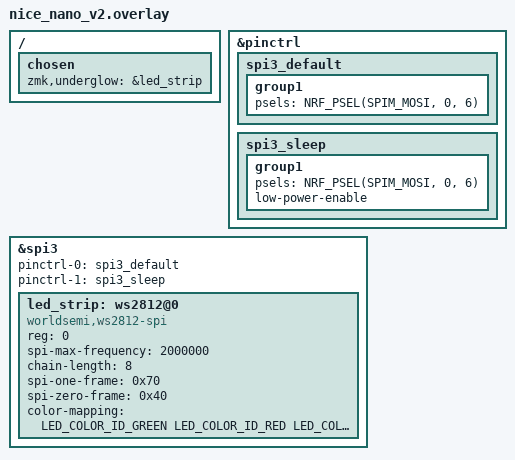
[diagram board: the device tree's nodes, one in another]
#include <dt-bindings/led/led.h>

/ {
    chosen {
        zmk,underglow = &led_strip;
    };
};

&pinctrl {
    spi3_default: spi3_default {
        group1 { psels = <NRF_PSEL(SPIM_MOSI, 0, 6)>; };
    };

    spi3_sleep: spi3_sleep {
        group1 {
            psels = <NRF_PSEL(SPIM_MOSI, 0, 6)>;
            low-power-enable;
        };
    };
};

&spi3 {
    status = "okay";
    pinctrl-0 = <&spi3_default>;
    pinctrl-1 = <&spi3_sleep>;
    pinctrl-names = "default", "sleep";

    /* Supprime le ws2812@0 défini par le shield, puis le recrée avec TON chain-length */
    /delete-node/ ws2812@0;

    led_strip: ws2812@0 {
        compatible = "worldsemi,ws2812-spi";
        reg = <0>;
        spi-max-frequency = <2000000>;

        chain-length = <8>;   /* mets 8 pour tester */
        spi-one-frame = <0x70>;
        spi-zero-frame = <0x40>;
        color-mapping = <LED_COLOR_ID_GREEN LED_COLOR_ID_RED LED_COLOR_ID_BLUE>;
    };
};
